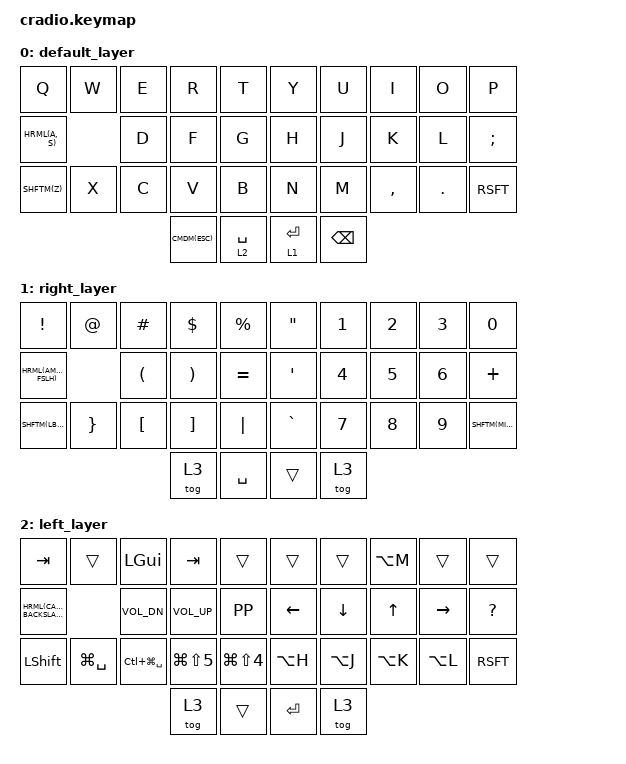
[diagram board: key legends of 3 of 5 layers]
// Copyright (c) 2022 The ZMK Contributors
// SPDX-License-Identifier: MIT

#define ZMK_POINTING_DEFAULT_MOVE_VAL 1500  // default: 600
#define ZMK_POINTING_DEFAULT_SCRL_VAL 20    // default: 10

#include <behaviors.dtsi>
#include <dt-bindings/zmk/keys.h>
#include <dt-bindings/zmk/bt.h>
#include <dt-bindings/zmk/pointing.h>

// Shift    LSHFT - LS()
// Option   LALT  - LA()
// Control  LCTRL - RC()
// Command  LGUI  - LG()

// Home row mods macro
#define HRML(k1,k2) &ht LCTRL k1 &ht LALT k2
#define SHFTM(k1) &ht LSHFT k1
#define CMDM(k1) &cmd_ht LGUI k1

&lt {
    tapping-term-ms = <180>;
};

/ {
    behaviors {
        ht: hold_tap {
            compatible = "zmk,behavior-hold-tap";
            #binding-cells = <2>;
            flavor = "tap-preferred";
            tapping-term-ms = <180>;
            quick-tap-ms = <150>;
            require-prior-idle-ms = <100>;
            bindings = <&kp>, <&kp>;
        };
        cmd_ht: cmd_hold_tap {
            compatible = "zmk,behavior-hold-tap";
            #binding-cells = <2>;
            flavor = "balanced";
            tapping-term-ms = <180>;
            quick-tap-ms = <150>;
            require-prior-idle-ms = <100>;
            bindings = <&kp>, <&kp>;
        };
    };
    
    keymap {
        compatible = "zmk,keymap";
        // 0
        default_layer {
            bindings = <
        //╭──────────┬──────────┬──────────┬──────────┬──────────╮   ╭──────────┬──────────┬──────────┬──────────┬──────────╮
        //│  Q       │  W       │  E       │  R       │  T       │   │  Y       │  U       │  I       │  O       │  P       │
            &kp Q      &kp W      &kp E      &kp R      &kp T          &kp Y      &kp U      &kp I      &kp O      &kp P
        //├──────────┼──────────┼──────────┼──────────┼──────────┤   ├──────────┼──────────┼──────────┼──────────┼──────────┤
        //│  A       │  S       │  D       │  F       │  G       │   │  H       │  J       │  K       │  L       │ ; and :  │
            HRML(A,        S)     &kp D      &kp F      &kp G          &kp H      &kp J      &kp K      &kp L      &kp SEMI
        //├──────────┼──────────┼──────────┼──────────┼──────────┤   ├──────────┼──────────┼──────────┼──────────┼──────────┤
        //│  z       │  x       │  c       │  v       │  b       │   │  n       │  m       │ , and lt │ . and gt │ shft     │
            SHFTM(Z)   &kp X      &kp C      &kp V      &kp B          &kp N      &kp M      &kp COMMA  &kp DOT    &kp RSFT
        //╰──────────┴──────────┴──────────┼──────────┼──────────┤   ├──────────┼──────────┼──────────┴──────────┴──────────╯
                                            CMDM(ESC)  &lt 2 SPACE    &lt 1 ENTER &kp BSPC
        //                                 ╰──────────┴──────────╯   ╰──────────┴──────────╯
            >;
        };

        // 1 (activated with right thumb)
        right_layer {
            bindings = <
        //╭──────────────┬────────────────┬───────────────┬───────────────┬──────────╮   ╭─────────────────┬──────────┬──────────┬──────────┬──────────╮
        //│ !            │  @             │  #            │  $            │ %        │   │ "               │ 1        │  2       │ 3        │  0       │
            &kp EXCL       &kp AT           &kp POUND       &kp DLLR        &kp PRCNT      &kp DQT           &kp N1     &kp N2     &kp N3     &kp N0
        //├──────────────┼────────────────┼───────────────┼───────────────┼──────────┤   ├─────────────────┼──────────┼──────────┼──────────┼──────────┤
        //│ &            │  /             │  (            │  )            │ =        │   │ '               │ 4        │ 5        │ 6        │  + LT(*) │
            HRML(AMPS,     FSLH)            &kp LPAR        &kp RPAR        &kp EQUAL      &kp SQT           &kp N4     &kp N5     &kp N6     &kp PLUS
        //├──────────────┼────────────────┼───────────────┼───────────────┼──────────┤   ├─────────────────┼──────────┼──────────┼──────────┼──────────┤
        //│ {            │  }             │  [            │  ]            │  |       │   │ `               │ 7        │ 8        │ 9        │ - and _  │
            SHFTM(LBRC)    &kp RBRC         &kp LBKT        &kp RBKT        &kp PIPE       &kp GRAVE         &kp N7     &kp N8     &kp N9     SHFTM(MINUS)
        //╰──────────────┴────────────────┴───────────────┼───────────────┼──────────┤   ├─────────────────┼──────────┼──────────┴──────────┴──────────╯
                                                            &tog 3          &kp SPACE      &trans            &tog 3 
        //                                                ╰───────────────┴──────────╯   ╰─────────────────┴──────────╯
            >;
        };

        // 2 (activated with left thumb)
        left_layer {
            bindings = <
        //╭──────────┬──────────┬────────────────────┬──────────────┬──────────────╮   ╭──────────┬──────────┬──────────┬──────────┬──────────╮
        //│  TAB     │          │                    │              │              │   │          │          │ SCRN FULL│          │          │
            &kp TAB    &trans     &kp LGUI             &kp TAB       &trans              &trans     &trans     &kp LA(M)  &trans     &trans
        //├──────────┼──────────┼────────────────────┼──────────────┼──────────────┤   ├──────────┼──────────┼──────────┼──────────┼──────────┤
        //│ CPS LCK  │ \        │ VOL DOWN           │  VOL UP      │  PLY/PAU     │   │  LEFT    │  DOWN    │  UP      │  RIGHT   │  ?       │
          HRML(CAPSLOCK, BACKSLASH) &kp K_VOL_DN       &kp K_VOL_UP   &kp K_PP           &kp LEFT   &kp DOWN   &kp UP     &kp RIGHT  &kp QMARK
        //├──────────┼──────────┼────────────────────┼──────────────┼──────────────┤   ├──────────┼──────────┼──────────┼──────────┼──────────┤
        //│  LSFT    │ FIND     │ EMOJI              │ SCRNREC      │ SCRNSHOT     │   │ SCRN LEFT│ SCRN DOWN│ SCRN UP  │ SCRN DOWN│ SHFT     │
            &kp LSHFT &kp LG(SPACE) &kp LC(LG(SPACE))  &kp LG(LS(N5)) &kp LG(LS(N4))     &kp LA(H)  &kp LA(J)  &kp LA(K)  &kp LA(L)  &kp RSFT
        //╰──────────┴──────────┴────────────────────┼──────────────┼──────────────┤   ├──────────┼──────────┼──────────┴──────────┴──────────╯
                                                       &tog 3         &trans             &kp ENTER  &tog 3 
        //                                           ╰──────────────┴──────────────╯   ╰──────────┴──────────╯
            >;
        };

        // 3
        mouse_layer {
            bindings = <
        //╭──────────┬──────────┬──────────┬──────────┬──────────╮   ╭───────────────┬───────────────┬───────────────┬───────────────┬───────────────╮
        //│          │          │          │ SYS LYR  │          │   │  BACK         │  U            │               │ FORWARD       │               │
            &trans     &trans     &trans     &mo 4      &trans          &mkp MB4       &kp U           &trans          &mkp MB5        &trans
        //├──────────┼──────────┼──────────┼──────────┼──────────┤   ├───────────────┼───────────────┼───────────────┼───────────────┼───────────────┤
        //│          │          │          │          │          │   │               │               │               │               │               │
            &trans     &trans     &kp D      &trans     &trans         &mmv MOVE_LEFT  &mmv MOVE_DOWN  &mmv MOVE_UP    &mmv MOVE_RIGHT &trans
        //├──────────┼──────────┼──────────┼──────────┼──────────┤   ├───────────────┼───────────────┼───────────────┼───────────────┼───────────────┤
        //│          │          │          │          │          │   │ SCROLL LEFT   │ SCROLL UP     │ SCROLL DOWN   │ SCROLL RIGHT  │               │
            &kp Z      &kp X     &kp C       &kp V      &kp B          &msc SCRL_LEFT  &msc SCRL_UP    &msc SCRL_DOWN  &msc SCRL_RIGHT &trans
        //╰──────────┴──────────┴──────────┼──────────┼──────────┤   ├───────────────┼───────────────┼───────────────┴───────────────┴───────────────╯
                                             &kp LGUI   &tog 3         &mkp LCLK       &mkp RCLK
        //                                 ╰──────────┴──────────╯   ╰───────────────┴───────────────╯
            >;
        };

        // 4
        sys_layer {
            bindings = <
        //╭──────────┬──────────┬──────────┬──────────┬──────────╮   ╭──────────┬──────────┬──────────┬──────────┬──────────╮
        //│ RESET    │          │          │          │PROFILE 0 │   │          │          │          │          │  RESET   │
           &sys_reset  &trans     &trans     &trans    &bt BT_SEL 0    &trans     &trans     &trans     &trans    &sys_reset
        //├──────────┼──────────┼──────────┼──────────┼──────────┤   ├──────────┼──────────┼──────────┼──────────┼──────────┤
        //│BOOTLOADER│          │          │          │PROFILE 1 │   │          │          │          │          │BOOTLOADER│
          &bootloader  &trans     &trans     &trans    &bt BT_SEL 1    &trans     &trans     &trans     &trans    &bootloader
        //├──────────┼──────────┼──────────┼──────────┼──────────┤   ├──────────┼──────────┼──────────┼──────────┼──────────┤
        //│          │          │          │ CLEAR BT │PROFILE 2 │   │          │          │          │          │          │
            &trans     &trans     &trans    &bt BT_CLR &bt BT_SEL 2    &trans     &trans     &trans     &trans     &trans
        //╰──────────┴──────────┴──────────┼──────────┼──────────┤   ├──────────┼──────────┼──────────┴──────────┴──────────╯
                                             &trans     &trans         &trans     &trans
        //                                 ╰──────────┴──────────╯   ╰──────────┴──────────╯
            >;
        };

    };
};
